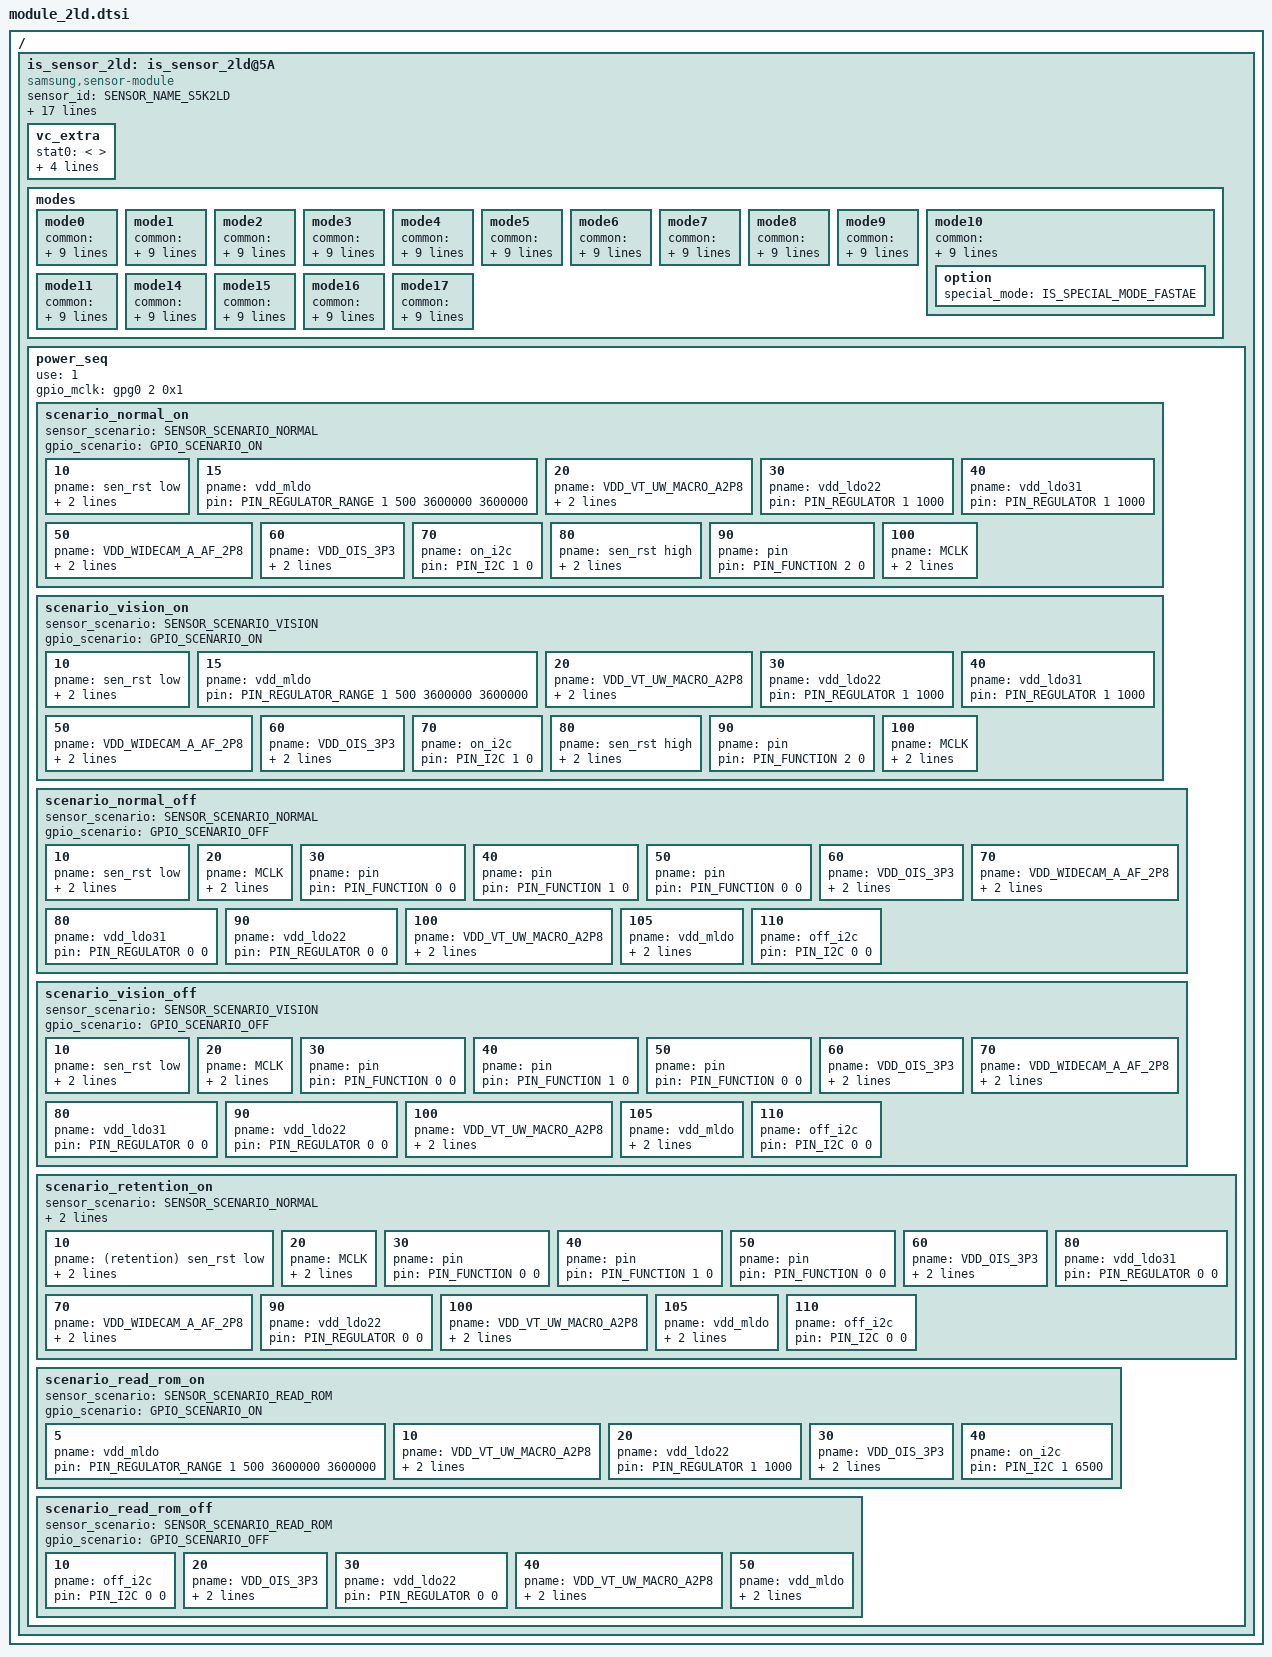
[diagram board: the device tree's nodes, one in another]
/*
 * SAMSUNG EXYNOSxxxx board camera device tree source
 *
 * Copyright (c) 2019 Samsung Electronics Co., Ltd.
 *		http://www.samsung.com
 *
 * This program is free software; you can redistribute it and/or modify
 * it under the terms of the GNU General Public License version 2 as
 * published by the Free Software Foundation.
 */

#include <dt-bindings/camera/exynos_is_dt.h>

/ {
	fragment@camera {
		target-path = "/";
		__overlay__ {
			is_sensor_2ld: is_sensor_2ld@5A {
				compatible = "samsung,sensor-module";

				/* common */
				sensor_id = <SENSOR_NAME_S5K2LD>;
				active_width = <4032>;
				active_height = <3024>;
				margin_left = <0>;
				margin_right = <0>;
				margin_top = <0>;
				margin_bottom = <0>;
				max_framerate = <480>;
				bitwidth = <10>;
				use_retention_mode = <SENSOR_RETENTION_INACTIVE>;
				sensor_maker = "SLSI";
				sensor_name = "S5K2LD";
				setfile_name = "setfile_2ld.bin";
				pinning_setfile;
				preload_setfile;

				status = "okay";

				/* vendor */
				rom_type = <2>; /* ROM_TYPE_EEPROM */
				rom_id = <0>;
				rom_cal_index = <0>;

				vc_extra {
					/* ex) statX = <stat_type, sensor_mode, max_width, max_height, max_element> */
					stat0 = </* not avaliable */>;									/* VC_BUF_DATA_TYPE_SENSOR_STAT1 */
					stat1 = </*VC_STAT_TYPE_PDP_4_0_PDAF_STAT0*/ 1100 /*VC_SENSOR_MODE_2PD_MODE3*/ 102 4032 756 2>;	/* VC_BUF_DATA_TYPE_GENERAL_STAT1 */
					stat2 = </* not avaliable */>;									/* VC_BUF_DATA_TYPE_SENSOR_STAT2 */
					stat3 = </*VC_STAT_TYPE_PDP_4_0_PDAF_STAT1*/ 1101 /*VC_SENSOR_MODE_2PD_MODE3*/ 102 4032 756 2>;	/* VC_BUF_DATA_TYPE_GENERAL_STAT2 */
					stat_vc = <2>; /* STAT out VC after CSIS link */
				};

				/* sensor modes */
				modes {
						/* common = <width, height, fps, settle, mode, lane, speed, interleave, lrte, pd_mode> */
						/* vcX = <map, hwformat, width, height, hwformat, type, width, height> */
					mode0 {
						common = <4032 3024 30 0 0 CSI_DATA_LANES_3 2964 CSI_MODE_VC_DT LRTE_ENABLE PD_MOD3>;
						vc0 = </* in */ 0 HW_FORMAT_RAW10 4032 3024	/* out */ HW_FORMAT_RAW10 VC_NOTHING 4032 3024>;
						vc1 = </* in */ 2 HW_FORMAT_UNKNOWN 0 0		/* out */ HW_FORMAT_UNKNOWN VC_NOTHING 0 0>;
						vc2 = </* in */ 1 HW_FORMAT_RAW10_POTF 4032 756	/* out */ HW_FORMAT_RAW10 VC_NOTHING 0 0>;
						vc3 = </* in */ 0 HW_FORMAT_EMBEDDED_8BIT 4032 2/* out */ HW_FORMAT_UNKNOWN VC_NOTHING 0 0>;
					};
					mode1 {
						common = <4032 3024 60 0 1 CSI_DATA_LANES_3 2964 CSI_MODE_VC_DT LRTE_ENABLE PD_MOD3>;
						vc0 = </* in */ 0 HW_FORMAT_RAW10 4032 3024	/* out */ HW_FORMAT_RAW10 VC_NOTHING 4032 3024>;
						vc1 = </* in */ 2 HW_FORMAT_UNKNOWN 0 0		/* out */ HW_FORMAT_UNKNOWN VC_NOTHING 0 0>;
						vc2 = </* in */ 1 HW_FORMAT_RAW10_POTF 4032 756	/* out */ HW_FORMAT_RAW10 VC_NOTHING 0 0>;
						vc3 = </* in */ 0 HW_FORMAT_EMBEDDED_8BIT 4032 2/* out */ HW_FORMAT_UNKNOWN VC_NOTHING 0 0>;
					};
					mode2 {
						common = <4032 2268 60 0 2 CSI_DATA_LANES_3 2964 CSI_MODE_VC_DT LRTE_ENABLE PD_MOD3>;
						vc0 = </* in */ 0 HW_FORMAT_RAW10 4032 2268	/* out */ HW_FORMAT_RAW10 VC_NOTHING 4032 2268>;
						vc1 = </* in */ 2 HW_FORMAT_UNKNOWN 0 0		/* out */ HW_FORMAT_UNKNOWN VC_NOTHING 0 0>;
						vc2 = </* in */ 1 HW_FORMAT_RAW10_POTF 4032 566	/* out */ HW_FORMAT_RAW10 VC_NOTHING 0 0>;
						vc3 = </* in */ 0 HW_FORMAT_EMBEDDED_8BIT 4032 2/* out */ HW_FORMAT_UNKNOWN VC_NOTHING 0 0>;
					};
					mode3 {
						common = <4032 2268 30 0 3 CSI_DATA_LANES_3 2964 CSI_MODE_VC_DT LRTE_ENABLE PD_MOD3>;
						vc0 = </* in */ 0 HW_FORMAT_RAW10 4032 2268	/* out */ HW_FORMAT_RAW10 VC_NOTHING 4032 2268>;
						vc1 = </* in */ 2 HW_FORMAT_UNKNOWN 0 0		/* out */ HW_FORMAT_UNKNOWN VC_NOTHING 0 0>;
						vc2 = </* in */ 1 HW_FORMAT_RAW10_POTF 4032 566	/* out */ HW_FORMAT_RAW10 VC_NOTHING 0 0>;
						vc3 = </* in */ 0 HW_FORMAT_EMBEDDED_8BIT 4032 2/* out */ HW_FORMAT_UNKNOWN VC_NOTHING 0 0>;
					};
					mode4 {
						common = <2016 1512 30 0 4 CSI_DATA_LANES_3 2964 CSI_MODE_VC_DT LRTE_ENABLE PD_MOD3>;
						vc0 = </* in */ 0 HW_FORMAT_RAW10 2016 1512	/* out */ HW_FORMAT_RAW10 VC_NOTHING 2016 1512>;
						vc1 = </* in */ 2 HW_FORMAT_UNKNOWN 0 0		/* out */ HW_FORMAT_UNKNOWN VC_NOTHING 0 0>;
						vc2 = </* in */ 1 HW_FORMAT_RAW10_POTF 2016 378	/* out */ HW_FORMAT_RAW10 VC_NOTHING 0 0>;
						vc3 = </* in */ 0 HW_FORMAT_EMBEDDED_8BIT 2016 2/* out */ HW_FORMAT_UNKNOWN VC_NOTHING 0 0>;
					};
					mode5 {
						common = <2016 1134 30 0 5 CSI_DATA_LANES_3 2964 CSI_MODE_VC_DT LRTE_ENABLE PD_MOD3>;
						vc0 = </* in */ 0 HW_FORMAT_RAW10 2016 1134	/* out */ HW_FORMAT_RAW10 VC_NOTHING 2016 1134>;
						vc1 = </* in */ 2 HW_FORMAT_UNKNOWN 0 0		/* out */ HW_FORMAT_UNKNOWN VC_NOTHING 0 0>;
						vc2 = </* in */ 1 HW_FORMAT_RAW10_POTF 2016 282	/* out */ HW_FORMAT_RAW10 VC_NOTHING 0 0>;
						vc3 = </* in */ 0 HW_FORMAT_EMBEDDED_8BIT 2016 2/* out */ HW_FORMAT_UNKNOWN VC_NOTHING 0 0>;
					};
					/* MODE 3 - 24fps LIVE FOCUS */
					mode6 {
						common = <4032 3024 24 0 6 CSI_DATA_LANES_3 2964 CSI_MODE_VC_DT LRTE_ENABLE PD_MOD3 EX_LIVEFOCUS>;
						vc0 = </* in */ 0 HW_FORMAT_RAW10 4032 3024	/* out */ HW_FORMAT_RAW10 VC_NOTHING 4032 3024>;
						vc1 = </* in */ 2 HW_FORMAT_UNKNOWN 0 0		/* out */ HW_FORMAT_UNKNOWN VC_NOTHING 0 0>;
						vc2 = </* in */ 1 HW_FORMAT_RAW10_POTF 4032 756	/* out */ HW_FORMAT_RAW10 VC_NOTHING 0 0>;
						vc3 = </* in */ 0 HW_FORMAT_EMBEDDED_8BIT 4032 2/* out */ HW_FORMAT_UNKNOWN VC_NOTHING 0 0>;
					};
					mode7 {
						common = <4032 2268 24 0 7 CSI_DATA_LANES_3 2964 CSI_MODE_VC_DT LRTE_ENABLE PD_MOD3 EX_LIVEFOCUS>;
						vc0 = </* in */ 0 HW_FORMAT_RAW10 4032 2268	/* out */ HW_FORMAT_RAW10 VC_NOTHING 4032 2268>;
						vc1 = </* in */ 2 HW_FORMAT_UNKNOWN 0 0		/* out */ HW_FORMAT_UNKNOWN VC_NOTHING 0 0>;
						vc2 = </* in */ 1 HW_FORMAT_RAW10_POTF 4032 566	/* out */ HW_FORMAT_RAW10 VC_TAILPDAF 4032 566>;
						vc3 = </* in */ 0 HW_FORMAT_EMBEDDED_8BIT 4032 2/* out */ HW_FORMAT_UNKNOWN VC_NOTHING 0 0>;
					};
					/* MODE 2 - SM */
					mode8 {
						common = <2016 1134 480 0 8 CSI_DATA_LANES_3 2964 CSI_MODE_VC_DT LRTE_ENABLE PD_NONE>;
						vc0 = </* in */ 0 HW_FORMAT_RAW10 2016 1134	/* out */ HW_FORMAT_RAW10 VC_NOTHING 2016 1134>;
						vc1 = </* in */ 2 HW_FORMAT_UNKNOWN 0 0		/* out */ HW_FORMAT_UNKNOWN VC_NOTHING 0 0>;
						vc2 = </* in */ 1 HW_FORMAT_UNKNOWN 0 0		/* out */ HW_FORMAT_UNKNOWN VC_NOTHING 0 0>;
						vc3 = </* in */ 0 HW_FORMAT_EMBEDDED_8BIT 2016 2/* out */ HW_FORMAT_UNKNOWN VC_NOTHING 0 0>;
					};
					mode9 {
						common = <2016 1134 240 0 9 CSI_DATA_LANES_3 2964 CSI_MODE_VC_DT LRTE_ENABLE PD_NONE>;
						vc0 = </* in */ 0 HW_FORMAT_RAW10 2016 1134	/* out */ HW_FORMAT_RAW10 VC_NOTHING 2016 1134>;
						vc1 = </* in */ 2 HW_FORMAT_UNKNOWN 0 0		/* out */ HW_FORMAT_UNKNOWN VC_NOTHING 0 0>;
						vc2 = </* in */ 1 HW_FORMAT_UNKNOWN 0 0		/* out */ HW_FORMAT_UNKNOWN VC_NOTHING 0 0>;
						vc3 = </* in */ 0 HW_FORMAT_EMBEDDED_8BIT 2016 2/* out */ HW_FORMAT_UNKNOWN VC_NOTHING 0 0>;
					};
					/* MODE 2 */
					mode10 {
						common = <1008 756 120 0 10 CSI_DATA_LANES_3 2964 CSI_MODE_VC_DT LRTE_DISABLE PD_NONE>;
						vc0 = </* in */ 0 HW_FORMAT_RAW10 1008 756	/* out */ HW_FORMAT_RAW10 VC_NOTHING 1008 756>;
						vc1 = </* in */ 2 HW_FORMAT_UNKNOWN 0 0		/* out */ HW_FORMAT_UNKNOWN VC_NOTHING 0 0>;
						vc2 = </* in */ 1 HW_FORMAT_UNKNOWN 0 0		/* out */ HW_FORMAT_UNKNOWN VC_NOTHING 0 0>;
						vc3 = </* in */ 0 HW_FORMAT_EMBEDDED_8BIT 1008 2/* out */ HW_FORMAT_UNKNOWN VC_NOTHING 0 0>;
						option { special_mode = <IS_SPECIAL_MODE_FASTAE>; };
					};
					/* MODE 2 - SSM */
					mode11 {
						common = <2016 1134 60 0 11 CSI_DATA_LANES_3 2964 CSI_MODE_VC_DT LRTE_ENABLE PD_NONE EX_DUALFPS_960>;
						vc0 = </* in */ 0 HW_FORMAT_RAW10_SDC 1416 1134		/* out */ HW_FORMAT_RAW8_SDC VC_NOTHING 1776 566>;
						vc1 = </* in */ 2 HW_FORMAT_UNKNOWN 0 0			/* out */ HW_FORMAT_UNKNOWN VC_NOTHING 0 0>;
						vc2 = </* in */ 0 HW_FORMAT_EMBEDDED_8BIT 1416 4	/* out */ HW_FORMAT_EMBEDDED_8BIT VC_EMBEDDED 1416 4>;
						vc3 = </* in */ 1 HW_FORMAT_UNKNOWN 0 0			/* out */ HW_FORMAT_UNKNOWN VC_NOTHING 0 0>;
					};
					mode14 {
						common = <1280 720 60 0 14 CSI_DATA_LANES_3 2964 CSI_MODE_VC_DT LRTE_ENABLE PD_NONE EX_DUALFPS_960>;
						vc0 = </* in */ 0 HW_FORMAT_RAW10 1280 720		/* out */ HW_FORMAT_RAW10 VC_NOTHING 1280 360>;
						vc1 = </* in */ 2 HW_FORMAT_UNKNOWN 0 0			/* out */ HW_FORMAT_UNKNOWN VC_NOTHING 0 0>;
						vc2 = </* in */ 0 HW_FORMAT_EMBEDDED_8BIT 1280 2	/* out */ HW_FORMAT_EMBEDDED_8BIT VC_EMBEDDED 1280 2>;
						vc3 = </* in */ 1 HW_FORMAT_UNKNOWN 0 0			/* out */ HW_FORMAT_UNKNOWN VC_NOTHING 0 0>;
					};
					/* MODE 3 PRO VIDEO */
					mode15 {
						common = <4032 2268 120 0 15 CSI_DATA_LANES_3 2964 CSI_MODE_VC_DT LRTE_ENABLE PD_MOD3>;
						vc0 = </* in */ 0 HW_FORMAT_RAW10 4032 2268	/* out */ HW_FORMAT_RAW10 VC_NOTHING 4032 2268>;
						vc1 = </* in */ 2 HW_FORMAT_UNKNOWN 0 0		/* out */ HW_FORMAT_UNKNOWN VC_NOTHING 0 0>;
						vc2 = </* in */ 1 HW_FORMAT_RAW10_POTF 4032 566	/* out */ HW_FORMAT_RAW10 VC_TAILPDAF 4032 566>;
						vc3 = </* in */ 0 HW_FORMAT_EMBEDDED_8BIT 4032 2/* out */ HW_FORMAT_UNKNOWN VC_NOTHING 0 0>;
					};
					mode16 {
						common = <3328 1872 120 0 16 CSI_DATA_LANES_3 2964 CSI_MODE_VC_DT LRTE_ENABLE PD_MOD3>;
						vc0 = </* in */ 0 HW_FORMAT_RAW10 3328 1872	/* out */ HW_FORMAT_RAW10 VC_NOTHING 3328 1872>;
						vc1 = </* in */ 2 HW_FORMAT_UNKNOWN 0 0		/* out */ HW_FORMAT_UNKNOWN VC_NOTHING 0 0>;
						vc2 = </* in */ 1 HW_FORMAT_RAW10_POTF 3328 468	/* out */ HW_FORMAT_RAW10 VC_TAILPDAF 3328 468>;
						vc3 = </* in */ 0 HW_FORMAT_EMBEDDED_8BIT 3328 2/* out */ HW_FORMAT_UNKNOWN VC_NOTHING 0 0>;
					};
					mode17 {
						common = <2800 2100 30 0 17 CSI_DATA_LANES_3 2964 CSI_MODE_VC_DT LRTE_ENABLE PD_MOD3 EX_LIVEFOCUS>;
						vc0 = </* in */ 0 HW_FORMAT_RAW10 2800 2100	/* out */ HW_FORMAT_RAW10 VC_NOTHING 2800 2100>;
						vc1 = </* in */ 2 HW_FORMAT_UNKNOWN 0 0			/* out */ HW_FORMAT_UNKNOWN VC_NOTHING 0 0>;
						vc2 = </* in */ 1 HW_FORMAT_RAW10_POTF 2800 524	/* out */ HW_FORMAT_RAW10 VC_TAILPDAF 2800 524>;
						vc3 = </* in */ 0 HW_FORMAT_EMBEDDED_8BIT 2800 2/* out */ HW_FORMAT_UNKNOWN VC_NOTHING 0 0>;
					};
				};

				power_seq {
					use = <1>;
					gpio_mclk = <&gpg0 2 0x1>;
					scenario_normal_on {
						sensor_scenario = <SENSOR_SCENARIO_NORMAL>;
						gpio_scenario = <GPIO_SCENARIO_ON>;

						/* A start node number should be over the 10 for reserved number 0~9. */
						/* pname = "name"; pin = <act value delay voltage>; gpio = <gpx# # 0x1>; */
						10 { pname = "sen_rst low"; pin = <PIN_OUTPUT 0 500>; gpio = <&gpg1 1 0x1>; };
						15 { pname = "vdd_mldo"; pin = <PIN_REGULATOR_RANGE 1 500 3600000 3600000>; };
						20 { pname = "VDD_VT_UW_MACRO_A2P8"; pin = <PIN_OUTPUT 1 0 1000>; gpio = <&gpm12 0 0x1>; };
						30 { pname = "vdd_ldo22"; pin = <PIN_REGULATOR 1 1000>; };
						40 { pname = "vdd_ldo31"; pin = <PIN_REGULATOR 1 1000>; };
						50 { pname = "VDD_WIDECAM_A_AF_2P8"; pin = <PIN_OUTPUT 1 2000>; gpio = <&gpp2 5 0x1>; };
						60 { pname = "VDD_OIS_3P3"; pin = <PIN_OUTPUT 1 1000>; gpio = <&gpp2 4 0x1>; };
						70 { pname = "on_i2c"; pin = <PIN_I2C 1 0>; };
						80 { pname = "sen_rst high"; pin = <PIN_OUTPUT 1 0>; gpio = <&gpg1 1 0x1>; };
						90 { pname = "pin"; pin = <PIN_FUNCTION 2 0>; };
						100 { pname = "MCLK"; pin = <PIN_MCLK 1 13000>; gpio = <&gpg0 2 0x1>; };
					};

					scenario_vision_on {
						sensor_scenario = <SENSOR_SCENARIO_VISION>;
						gpio_scenario = <GPIO_SCENARIO_ON>;

						/* A start node number should be over the 10 for reserved number 0~9. */
						/* pname = "name"; pin = <act value delay voltage>; gpio = <gpx# # 0x1>; */
						10 { pname = "sen_rst low"; pin = <PIN_OUTPUT 0 500>; gpio = <&gpg1 1 0x1>; };
						15 { pname = "vdd_mldo"; pin = <PIN_REGULATOR_RANGE 1 500 3600000 3600000>; };
						20 { pname = "VDD_VT_UW_MACRO_A2P8"; pin = <PIN_OUTPUT 1 0 1000>; gpio = <&gpm12 0 0x1>; };
						30 { pname = "vdd_ldo22"; pin = <PIN_REGULATOR 1 1000>; };
						40 { pname = "vdd_ldo31"; pin = <PIN_REGULATOR 1 1000>; };
						50 { pname = "VDD_WIDECAM_A_AF_2P8"; pin = <PIN_OUTPUT 1 2000>; gpio = <&gpp2 5 0x1>; };
						60 { pname = "VDD_OIS_3P3"; pin = <PIN_OUTPUT 1 1000>; gpio = <&gpp2 4 0x1>; };
						70 { pname = "on_i2c"; pin = <PIN_I2C 1 0>; };
						80 { pname = "sen_rst high"; pin = <PIN_OUTPUT 1 0>; gpio = <&gpg1 1 0x1>; };
						90 { pname = "pin"; pin = <PIN_FUNCTION 2 0>; };
						100 { pname = "MCLK"; pin = <PIN_MCLK 1 13000>; gpio = <&gpg0 2 0x1>; };
					};

					scenario_normal_off {
						sensor_scenario = <SENSOR_SCENARIO_NORMAL>;
						gpio_scenario = <GPIO_SCENARIO_OFF>;

						/* A start node number should be over the 10 for reserved number 0~9. */
						/* pname = "name"; pin = <act value delay voltage>; gpio = <gpx# # 0x1>; */
						10 { pname = "sen_rst low"; pin = <PIN_OUTPUT 0 500>; gpio = <&gpg1 1 0x1>; };
						20 { pname = "MCLK"; pin = <PIN_MCLK 0 500>; gpio = <&gpg0 2 0x1>; };
						30 { pname = "pin"; pin = <PIN_FUNCTION 0 0>; };
						40 { pname = "pin"; pin = <PIN_FUNCTION 1 0>; };
						50 { pname = "pin"; pin = <PIN_FUNCTION 0 0>; };
						60 { pname = "VDD_OIS_3P3"; pin = <PIN_OUTPUT 0 1000>; gpio = <&gpp2 4 0x1>; };
						70 { pname = "VDD_WIDECAM_A_AF_2P8"; pin = <PIN_OUTPUT 0 1000>; gpio = <&gpp2 5 0x1>; };
						80 { pname = "vdd_ldo31"; pin = <PIN_REGULATOR 0 0>; };
						90 { pname = "vdd_ldo22"; pin = <PIN_REGULATOR 0 0>; };
						100 { pname = "VDD_VT_UW_MACRO_A2P8"; pin = <PIN_OUTPUT 0 1000>; gpio = <&gpm12 0 0x1>; };
						105 { pname = "vdd_mldo"; pin = <PIN_REGULATOR_RANGE 0 1000 3400000 3600000>; };
						110 { pname = "off_i2c"; pin = <PIN_I2C 0 0>; };
					};

					scenario_vision_off {
						sensor_scenario = <SENSOR_SCENARIO_VISION>;
						gpio_scenario = <GPIO_SCENARIO_OFF>;

						/* A start node number should be over the 10 for reserved number 0~9. */
						/* pname = "name"; pin = <act value delay voltage>; gpio = <gpx# # 0x1>; */

						/* A start node number should be over the 10 for reserved number 0~9. */
						/* pname = "name"; pin = <act value delay voltage>; gpio = <gpx# # 0x1>; */
						10 { pname = "sen_rst low"; pin = <PIN_OUTPUT 0 500>; gpio = <&gpg1 1 0x1>; };
						20 { pname = "MCLK"; pin = <PIN_MCLK 0 500>; gpio = <&gpg0 2 0x1>; };
						30 { pname = "pin"; pin = <PIN_FUNCTION 0 0>; };
						40 { pname = "pin"; pin = <PIN_FUNCTION 1 0>; };
						50 { pname = "pin"; pin = <PIN_FUNCTION 0 0>; };
						60 { pname = "VDD_OIS_3P3"; pin = <PIN_OUTPUT 0 1000>; gpio = <&gpp2 4 0x1>; };
						70 { pname = "VDD_WIDECAM_A_AF_2P8"; pin = <PIN_OUTPUT 0 1000>; gpio = <&gpp2 5 0x1>; };
						80 { pname = "vdd_ldo31"; pin = <PIN_REGULATOR 0 0>; };
						90 { pname = "vdd_ldo22"; pin = <PIN_REGULATOR 0 0>; };
						100 { pname = "VDD_VT_UW_MACRO_A2P8"; pin = <PIN_OUTPUT 0 1000>; gpio = <&gpm12 0 0x1>; };
						105 { pname = "vdd_mldo"; pin = <PIN_REGULATOR_RANGE 0 1000 3400000 3600000>; };
						110 { pname = "off_i2c"; pin = <PIN_I2C 0 0>; };
					};

					scenario_retention_on {
						sensor_scenario = <SENSOR_SCENARIO_NORMAL>;
						gpio_scenario = <GPIO_SCENARIO_SENSOR_RETENTION_ON>;

						/* A start node number should be over the 10 for reserved number 0~9. */
						/* pname = "name"; pin = <act value delay voltage>; gpio = <gpx# # 0x1>; */
						10 { pname = "(retention) sen_rst low"; pin = <PIN_OUTPUT 0 10>; gpio = <&gpg1 1 0x1>; };
						20 { pname = "MCLK"; pin = <PIN_MCLK 0 500>; gpio = <&gpg0 2 0x1>; };
						30 { pname = "pin"; pin = <PIN_FUNCTION 0 0>; };
						40 { pname = "pin"; pin = <PIN_FUNCTION 1 0>; };
						50 { pname = "pin"; pin = <PIN_FUNCTION 0 0>; };
						60 { pname = "VDD_OIS_3P3"; pin = <PIN_OUTPUT 0 1000>; gpio = <&gpp2 4 0x1>; };
						70 { pname = "VDD_WIDECAM_A_AF_2P8"; pin = <PIN_OUTPUT 0 1000>; gpio = <&gpp2 5 0x1>; };
						80 { pname = "vdd_ldo31"; pin = <PIN_REGULATOR 0 0>; };
						90 { pname = "vdd_ldo22"; pin = <PIN_REGULATOR 0 0>; };
						100 { pname = "VDD_VT_UW_MACRO_A2P8"; pin = <PIN_OUTPUT 0 1000>; gpio = <&gpm12 0 0x1>; };
						105 { pname = "vdd_mldo"; pin = <PIN_REGULATOR_RANGE 0 1000 3400000 3600000>; };
						110 { pname = "off_i2c"; pin = <PIN_I2C 0 0>; };
					};

					scenario_read_rom_on {
						sensor_scenario = <SENSOR_SCENARIO_READ_ROM>;
						gpio_scenario = <GPIO_SCENARIO_ON>;

						/* A start node number should be over the 10 for reserved number 0~9. */
						/* pname = "name"; pin = <act value delay voltage>; gpio = <gpx# # 0x1>; */
						5 { pname = "vdd_mldo"; pin = <PIN_REGULATOR_RANGE 1 500 3600000 3600000>; };
						10 { pname = "VDD_VT_UW_MACRO_A2P8"; pin = <PIN_OUTPUT 1 0 1000>; gpio = <&gpm12 0 0x1>; };
						20 { pname = "vdd_ldo22"; pin = <PIN_REGULATOR 1 1000>; };
						30 { pname = "VDD_OIS_3P3"; pin = <PIN_OUTPUT 1 1000>; gpio = <&gpp2 4 0x1>; };
						40 { pname = "on_i2c"; pin = <PIN_I2C 1 6500>; };
					};

					scenario_read_rom_off {
						sensor_scenario = <SENSOR_SCENARIO_READ_ROM>;
						gpio_scenario = <GPIO_SCENARIO_OFF>;

						/* A start node number should be over the 10 for reserved number 0~9. */
						/* pname = "name"; pin = <act value delay voltage>; gpio = <gpx# # 0x1>; */
						10 { pname = "off_i2c"; pin = <PIN_I2C 0 0>; };
						20 { pname = "VDD_OIS_3P3"; pin = <PIN_OUTPUT 0 1000>; gpio = <&gpp2 4 0x1>; };
						30 { pname = "vdd_ldo22"; pin = <PIN_REGULATOR 0 0>; };
						40 { pname = "VDD_VT_UW_MACRO_A2P8"; pin = <PIN_OUTPUT 0 1000>; gpio = <&gpm12 0 0x1>; };
						50 { pname = "vdd_mldo"; pin = <PIN_REGULATOR_RANGE 0 1000 3400000 3600000>; };
					};
				};
			};
		}; /* end of __overlay__ */
	}; /* end of fragment */
}; /* end of root */
